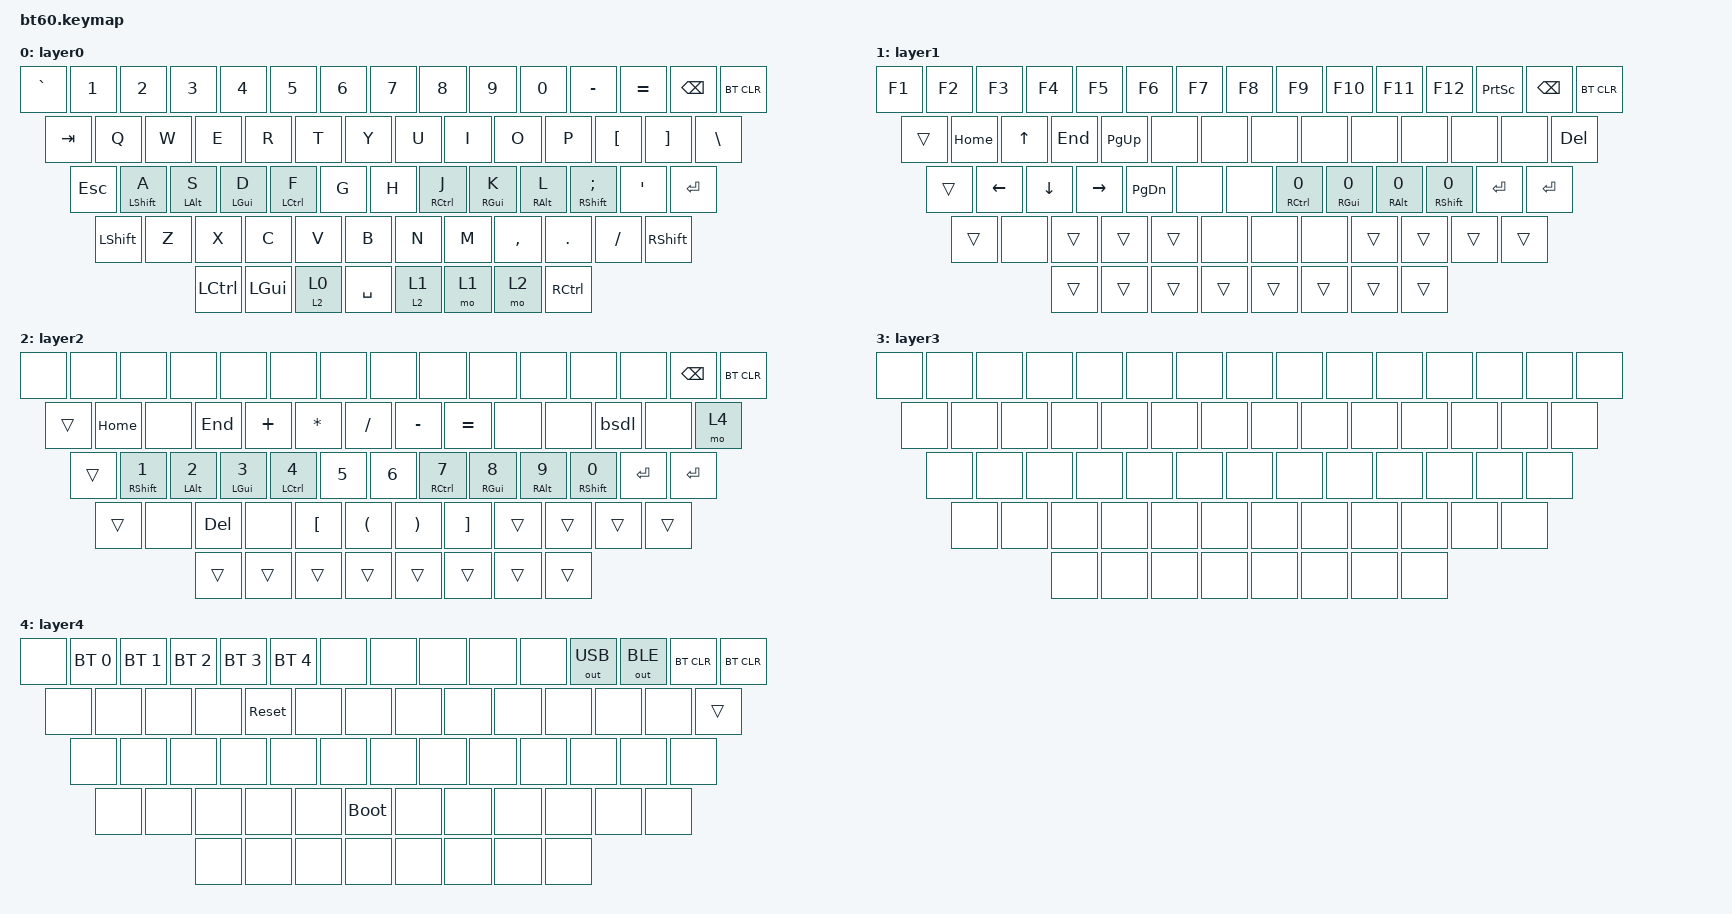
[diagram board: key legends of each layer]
#include <behaviors.dtsi>
#include <dt-bindings/zmk/keys.h>
#include <dt-bindings/zmk/bt.h>
#include <dt-bindings/zmk/outputs.h>

/ {
    	behaviors {
        	bsdl: backspace_delete {
            		compatible = "zmk,behavior-mod-morph";
            		#binding-cells = <0>;
            		bindings = <&kp BSPC>, <&kp DEL>;
            		mods = <(MOD_LSFT|MOD_RSFT)>;
        	};
		ltd: layer_holdtap {
            		compatible = "zmk,behavior-hold-tap";
            		#binding-cells = <2>;
            		tapping-term-ms = <250>;
            		quick_tap_ms = <0>;
            		flavor = "tap-preferred";
            		bindings = <&to>, <&to>;
        	};
		hm: homerow_mods {
            		compatible = "zmk,behavior-hold-tap";
            		#binding-cells = <2>;
            		tapping-term-ms = <250>;
            		quick_tap_ms = <0>;
            		flavor = "tap-preferred";
            		bindings = <&kp>, <&kp>;
       		};
        	
    	};
	keymap {
		compatible = "zmk,keymap";

		layer0 {
			bindings = <
				&kp GRAVE &kp N1 &kp N2 &kp N3 &kp N4 &kp N5 &kp N6 &kp N7 &kp N8 &kp N9 &kp N0 &kp MINUS &kp EQUAL &kp BSPC &bt BT_CLR
				&kp TAB &kp Q &kp W &kp E &kp R &kp T &kp Y &kp U &kp I &kp O &kp P &kp LBKT &kp RBKT &kp BSLH 
				&kp ESC &hm LSHFT A &hm LALT S &hm LGUI D &hm LCTRL F &kp G &kp H &hm RCTRL J &hm RGUI K &hm RALT L &hm RSHFT SEMI &kp APOS &kp ENTER
				&kp LSHFT &kp Z &kp X &kp C &kp V &kp B &kp N &kp M &kp COMMA &kp DOT &kp SLASH &kp RSHFT
				&kp LCTRL &kp LGUI &ltd 2 0 &kp SPACE &ltd 2 1 &mo 1 &mo 2 &kp RCTRL
			>;

			sensor-bindings = <&inc_dec_kp C_VOL_UP C_VOL_DN>;
		};

		layer1 {
			bindings = <
				&kp F1 &kp F2 &kp F3 &kp F4 &kp F5 &kp F6 &kp F7 &kp F8 &kp F9 &kp F10 &kp F11 &kp F12 &kp PSCRN &kp BSPC &bt BT_CLR
				&trans &kp HOME &kp UP &kp END &kp PAGE_UP &none &none &none &none &none &none &none &none &kp DEL
				&trans &kp LEFT &kp DOWN &kp RIGHT &kp PAGE_DOWN &none &none &hm RCTRL N0 &hm RGUI N0 &hm RALT N0 &hm RSHFT N0 &kp ENTER &kp ENTER
				&trans &none &trans &trans &trans &none &none &none &trans &trans &trans &trans
				&trans &trans &trans &trans &trans &trans &trans &trans
			>;

			sensor-bindings = <&inc_dec_kp C_VOL_UP C_VOL_DN>;
		};

		layer2 {
			bindings = <
				&none &none &none &none &none &none &none &none &none &none &none &none &none &kp BSPC &bt BT_CLR
				&trans &kp HOME &none &kp END &kp PLUS &kp STAR &kp SLASH &kp MINUS &kp EQUAL &none &none &bsdl &none &mo 4
				&trans &hm RSHFT N1 &hm LALT N2 &hm LGUI N3 &hm LCTRL N4 &kp N5 &kp N6 &hm RCTRL N7 &hm RGUI N8 &hm RALT N9 &hm RSHFT N0 &kp ENTER &kp ENTER	
				&trans &none &kp DEL &none &kp LBKT &kp LPAR &kp RPAR &kp RBKT &trans &trans &trans &trans 
				&trans &trans &trans &trans &trans &trans &trans &trans
			>;

			sensor-bindings = <&inc_dec_kp C_VOL_UP C_VOL_DN>;
		};

		layer3 {
			bindings = <
			&none &none &none &none &none &none &none &none &none &none &none &none &none &none &none &none &none &none &none &none &none &none &none &none &none &none &none &none &none &none &none &none &none &none &none &none &none &none &none &none &none &none &none &none &none &none &none &none &none &none &none &none &none &none &none &none &none &none &none &none &none  &none
			>;

			sensor-bindings = <&inc_dec_kp C_VOL_UP C_VOL_DN>;
		};

		layer4 {
			bindings = <
				&none &bt BT_SEL 0 &bt BT_SEL 1 &bt BT_SEL 2 &bt BT_SEL 3 &bt BT_SEL 4 &none &none &none &none &none &out OUT_USB &out OUT_BLE &bt BT_CLR &bt BT_CLR
				&none &none &none &none &sys_reset &none &none &none &none &none &none &none &none &trans
				&none &none &none &none &none &none &none &none &none &none &none &none &none
				&none &none &none &none &none &bootloader &none &none &none &none &none &none
				&none &none &none &none &none &none &none &none
			>;

			sensor-bindings = <&inc_dec_kp C_VOL_UP C_VOL_DN>;
		};


	};
};
